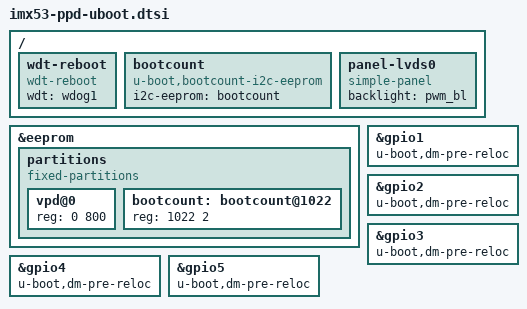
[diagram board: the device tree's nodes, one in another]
// SPDX-License-Identifier: GPL-2.0+ OR X11
/*
 * Copyright 2019 Collabora Ltd
 * Copyright 2019 General Electric Company
 */

/ {
	wdt-reboot {
		compatible = "wdt-reboot";
		wdt = <&wdog1>;
	};

	bootcount {
		compatible = "u-boot,bootcount-i2c-eeprom";
		i2c-eeprom = <&bootcount>;
	};

	panel-lvds0 {
		compatible = "simple-panel";
		backlight = <&pwm_bl>;
	};
};

&eeprom {
	partitions {
		compatible = "fixed-partitions";
		#address-cells = <1>;
		#size-cells = <1>;

		vpd@0 {
			reg = <0 800>;
		};

		bootcount: bootcount@1022 {
			reg = <1022 2>;
		};
	};
};

&gpio1 {
	u-boot,dm-pre-reloc;
};

&gpio2 {
	u-boot,dm-pre-reloc;
};

&gpio3 {
	u-boot,dm-pre-reloc;
};

&gpio4 {
	u-boot,dm-pre-reloc;
};

&gpio5 {
	u-boot,dm-pre-reloc;
};
